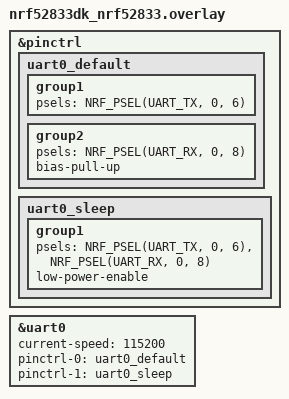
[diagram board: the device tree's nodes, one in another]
/*
 * Copyright (c) Nanopower Semiconductor AS
 * SPDX-License-Identifier: Apache-2.0
 *
 * boards/nrf52833dk_nrf52833.overlay
 * ------------------------------------
 * Board-specific additions to the npz2100 shield for the nrf52833dk_nrf52833 board.
 * Applied automatically on top of npz2100.overlay.
 *
 * UART0 uses TX on P0.06 and RX on P0.08 (115200 baud, no flow control).
 * The board's RTS (P0.05) and CTS (P0.07) are removed from both states, so
 * only TX and RX are routed. Neither pin is shared with the nPZ2100, which
 * uses P0.26/P0.27 on the Arduino I2C bus.
 */

&pinctrl {
	uart0_default: uart0_default {
		group1 {
			psels = <NRF_PSEL(UART_TX, 0, 6)>;
		};

		group2 {
			psels = <NRF_PSEL(UART_RX, 0, 8)>;
			bias-pull-up;
		};
	};

	uart0_sleep: uart0_sleep {
		group1 {
			psels = <NRF_PSEL(UART_TX, 0, 6)>,
				<NRF_PSEL(UART_RX, 0, 8)>;
			low-power-enable;
		};

		/delete-node/ group2;
	};
};

&uart0 {
	status = "okay";
	current-speed = <115200>;
	pinctrl-0 = <&uart0_default>;
	pinctrl-1 = <&uart0_sleep>;
	pinctrl-names = "default", "sleep";
};
